VERSION ""

NS_ :

BS_:

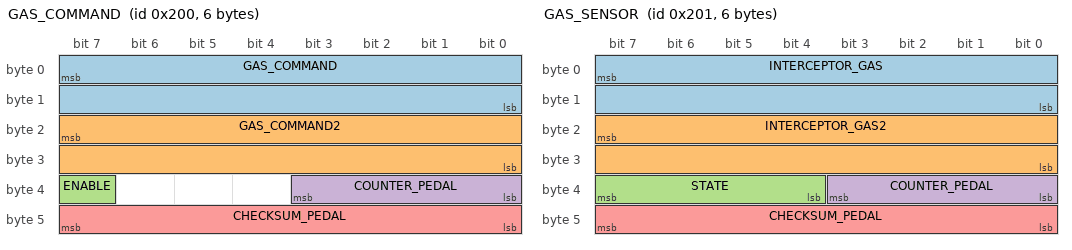
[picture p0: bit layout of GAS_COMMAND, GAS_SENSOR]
BO_ 512 GAS_COMMAND: 6 EON
 SG_ GAS_COMMAND : 7|16@0+ (0.253984064,-83.3) [0|1] "" INTERCEPTOR
 SG_ GAS_COMMAND2 : 23|16@0+ (0.126992032,-83.3) [0|1] "" INTERCEPTOR
 SG_ ENABLE : 39|1@0+ (1,0) [0|1] "" INTERCEPTOR
 SG_ COUNTER_PEDAL : 35|4@0+ (1,0) [0|15] "" INTERCEPTOR
 SG_ CHECKSUM_PEDAL : 47|8@0+ (1,0) [0|255] "" INTERCEPTOR

BO_ 513 GAS_SENSOR: 6 INTERCEPTOR
 SG_ INTERCEPTOR_GAS : 7|16@0+ (1,0) [0|1] "" EON
 SG_ INTERCEPTOR_GAS2 : 23|16@0+ (1,0) [0|1] "" EON
 SG_ STATE : 39|4@0+ (1,0) [0|15] "" EON
 SG_ COUNTER_PEDAL : 35|4@0+ (1,0) [0|15] "" EON
 SG_ CHECKSUM_PEDAL : 47|8@0+ (1,0) [0|255] "" EON

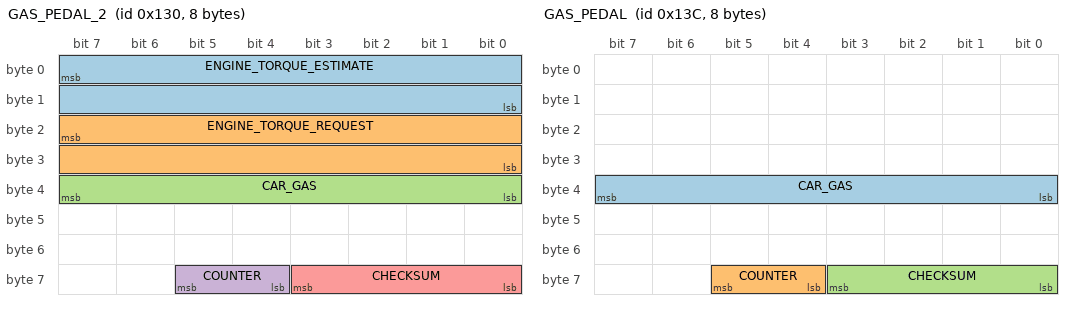
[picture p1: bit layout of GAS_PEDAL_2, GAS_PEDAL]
BO_ 304 GAS_PEDAL_2: 8 PCM
 SG_ ENGINE_TORQUE_ESTIMATE : 7|16@0- (1,0) [-1000|1000] "Nm" EON
 SG_ ENGINE_TORQUE_REQUEST : 23|16@0- (1,0) [-1000|1000] "Nm" EON
 SG_ CAR_GAS : 39|8@0+ (1,0) [0|255] "" EON
 SG_ COUNTER : 61|2@0+ (1,0) [0|3] "" EON
 SG_ CHECKSUM : 59|4@0+ (1,0) [0|15] "" EON

BO_ 316 GAS_PEDAL: 8 PCM
 SG_ CAR_GAS : 39|8@0+ (1,0) [0|255] "" EON
 SG_ COUNTER : 61|2@0+ (1,0) [0|3] "" EON
 SG_ CHECKSUM : 59|4@0+ (1,0) [0|15] "" EON

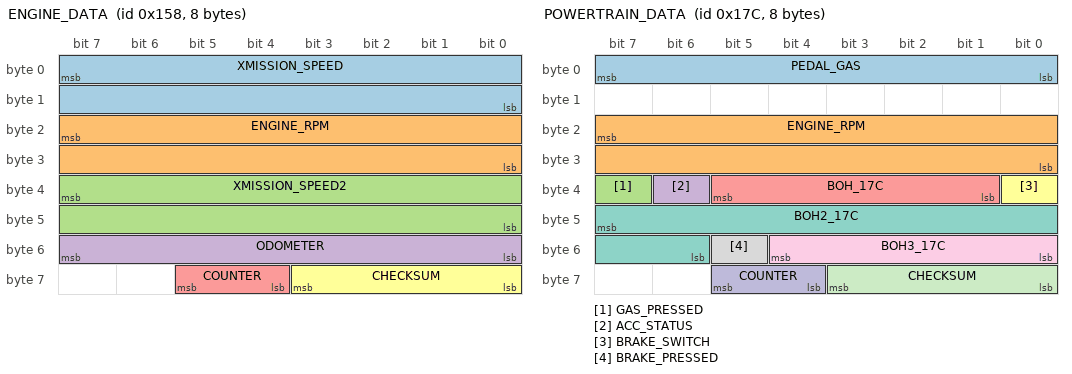
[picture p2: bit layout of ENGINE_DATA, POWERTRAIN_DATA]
BO_ 344 ENGINE_DATA: 8 PCM
 SG_ XMISSION_SPEED : 7|16@0+ (0.01,0) [0|250] "kph" EON
 SG_ ENGINE_RPM : 23|16@0+ (1,0) [0|15000] "rpm" EON
 SG_ XMISSION_SPEED2 : 39|16@0+ (0.01,0) [0|250] "kph" EON
 SG_ ODOMETER : 55|8@0+ (10,0) [0|2550] "m" XXX
 SG_ COUNTER : 61|2@0+ (1,0) [0|3] "" EON
 SG_ CHECKSUM : 59|4@0+ (1,0) [0|15] "" EON

BO_ 380 POWERTRAIN_DATA: 8 PCM
 SG_ PEDAL_GAS : 7|8@0+ (1,0) [0|255] "" EON
 SG_ ENGINE_RPM : 23|16@0+ (1,0) [0|15000] "rpm" EON
 SG_ GAS_PRESSED : 39|1@0+ (1,0) [0|1] "" EON
 SG_ ACC_STATUS : 38|1@0+ (1,0) [0|1] "" EON
 SG_ BOH_17C : 37|5@0+ (1,0) [0|1] "" EON
 SG_ BRAKE_SWITCH : 32|1@0+ (1,0) [0|1] "" EON
 SG_ BOH2_17C : 47|10@0+ (1,0) [0|1] "" EON
 SG_ BRAKE_PRESSED : 53|1@0+ (1,0) [0|1] "" EON
 SG_ BOH3_17C : 52|5@0+ (1,0) [0|1] "" EON
 SG_ COUNTER : 61|2@0+ (1,0) [0|3] "" EON
 SG_ CHECKSUM : 59|4@0+ (1,0) [0|15] "" EON

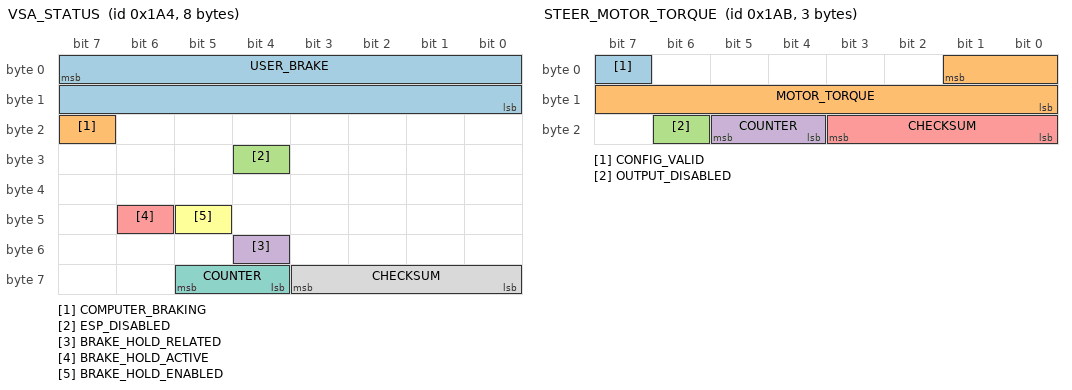
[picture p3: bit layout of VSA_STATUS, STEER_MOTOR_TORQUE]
BO_ 420 VSA_STATUS: 8 VSA
 SG_ USER_BRAKE : 7|16@0+ (0.015625,-1.609375) [0|1000] "" EON
 SG_ COMPUTER_BRAKING : 23|1@0+ (1,0) [0|1] "" EON
 SG_ ESP_DISABLED : 28|1@0+ (1,0) [0|1] "" EON
 SG_ BRAKE_HOLD_RELATED : 52|1@0+ (1,0) [0|1] "" XXX
 SG_ BRAKE_HOLD_ACTIVE : 46|1@0+ (1,0) [0|1] "" EON
 SG_ BRAKE_HOLD_ENABLED : 45|1@0+ (1,0) [0|1] "" EON
 SG_ COUNTER : 61|2@0+ (1,0) [0|3] "" EON
 SG_ CHECKSUM : 59|4@0+ (1,0) [0|15] "" EON

BO_ 427 STEER_MOTOR_TORQUE: 3 EPS
 SG_ CONFIG_VALID : 7|1@0+ (1,0) [0|1] "" EON
 SG_ MOTOR_TORQUE : 1|10@0+ (1,0) [0|256] "" EON
 SG_ OUTPUT_DISABLED : 22|1@0+ (1,0) [0|1] "" EON
 SG_ COUNTER : 21|2@0+ (1,0) [0|3] "" EON
 SG_ CHECKSUM : 19|4@0+ (1,0) [0|15] "" EON

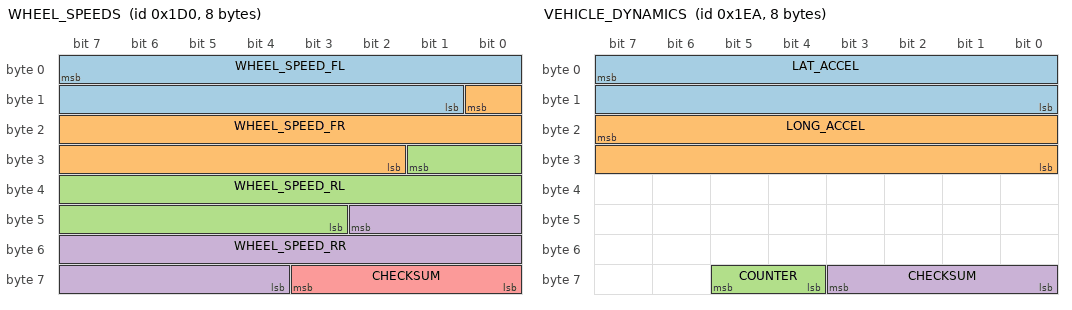
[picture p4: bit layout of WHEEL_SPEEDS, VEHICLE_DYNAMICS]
BO_ 464 WHEEL_SPEEDS: 8 VSA
 SG_ WHEEL_SPEED_FL : 7|15@0+ (0.01,0) [0|250] "kph" EON
 SG_ WHEEL_SPEED_FR : 8|15@0+ (0.01,0) [0|250] "kph" EON
 SG_ WHEEL_SPEED_RL : 25|15@0+ (0.01,0) [0|250] "kph" EON
 SG_ WHEEL_SPEED_RR : 42|15@0+ (0.01,0) [0|250] "kph" EON
 SG_ CHECKSUM : 59|4@0+ (1,0) [0|3] "" EON

BO_ 490 VEHICLE_DYNAMICS: 8 VSA
 SG_ LAT_ACCEL : 7|16@0- (0.0015,0) [-20|20] "m/s2" EON
 SG_ LONG_ACCEL : 23|16@0- (0.0015,0) [-20|20] "m/s2" EON
 SG_ COUNTER : 61|2@0+ (1,0) [0|3] "" EON
 SG_ CHECKSUM : 59|4@0+ (1,0) [0|3] "" EON

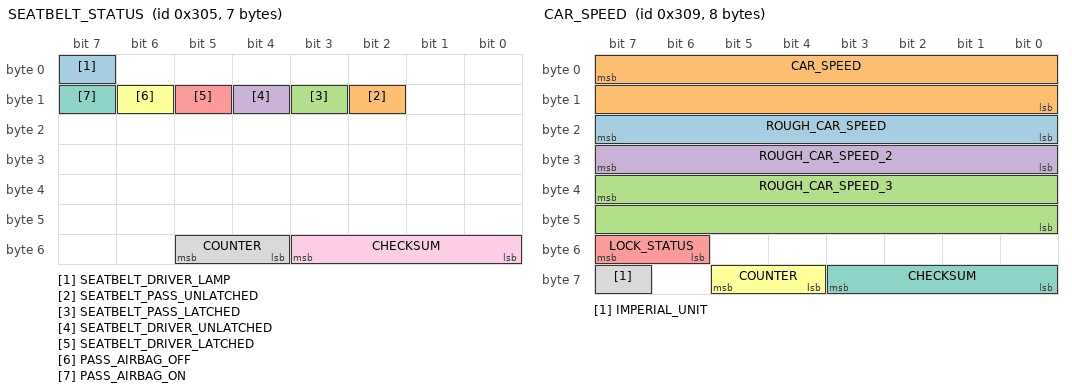
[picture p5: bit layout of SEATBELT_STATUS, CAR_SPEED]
BO_ 773 SEATBELT_STATUS: 7 BDY
 SG_ SEATBELT_DRIVER_LAMP : 7|1@0+ (1,0) [0|1] "" EON
 SG_ SEATBELT_PASS_UNLATCHED : 10|1@0+ (1,0) [0|1] "" EON
 SG_ SEATBELT_PASS_LATCHED : 11|1@0+ (1,0) [0|1] "" EON
 SG_ SEATBELT_DRIVER_UNLATCHED : 12|1@0+ (1,0) [0|1] "" EON
 SG_ SEATBELT_DRIVER_LATCHED : 13|1@0+ (1,0) [0|1] "" EON
 SG_ PASS_AIRBAG_OFF : 14|1@0+ (1,0) [0|1] "" EON
 SG_ PASS_AIRBAG_ON : 15|1@0+ (1,0) [0|1] "" EON
 SG_ COUNTER : 53|2@0+ (1,0) [0|3] "" EON
 SG_ CHECKSUM : 51|4@0+ (1,0) [0|3] "" EON

BO_ 777 CAR_SPEED: 8 PCM
 SG_ ROUGH_CAR_SPEED : 23|8@0+ (1,0) [0|255] "mph" XXX
 SG_ CAR_SPEED : 7|16@0+ (0.01,0) [0|65535] "kph" XXX
 SG_ ROUGH_CAR_SPEED_3 : 39|16@0+ (0.01,0) [0|65535] "kph" XXX
 SG_ ROUGH_CAR_SPEED_2 : 31|8@0+ (1,0) [0|255] "mph" XXX
 SG_ LOCK_STATUS : 55|2@0+ (1,0) [0|255] "" XXX
 SG_ COUNTER : 61|2@0+ (1,0) [0|3] "" XXX
 SG_ CHECKSUM : 59|4@0+ (1,0) [0|15] "" XXX
 SG_ IMPERIAL_UNIT : 63|1@0+ (1,0) [0|1] "" XXX

BO_ 780 ACC_HUD: 8 ADAS
 SG_ PCM_SPEED : 7|16@0+ (0.01,0) [0|250] "kph" BDY
 SG_ PCM_GAS : 23|8@0+ (1,0) [0|127] "" BDY
 SG_ CRUISE_SPEED : 31|8@0+ (1,0) [0|255] "kph" BDY
 SG_ DTC_MODE : 39|1@0+ (1,0) [0|1] "" BDY
 SG_ BOH : 38|1@0+ (1,0) [0|1] "" BDY
 SG_ ACC_PROBLEM : 37|1@0+ (1,0) [0|1] "" BDY
 SG_ FCM_OFF : 35|1@0+ (1,0) [0|1] "" BDY
 SG_ FCM_OFF_2 : 36|1@0+ (1,0) [0|1] "" BDY
 SG_ FCM_PROBLEM : 34|1@0+ (1,0) [0|1] "" BDY
 SG_ RADAR_OBSTRUCTED : 33|1@0+ (1,0) [0|1] "" BDY
 SG_ ENABLE_MINI_CAR : 32|1@0+ (1,0) [0|1] "" BDY
 SG_ HUD_DISTANCE : 47|2@0+ (1,0) [0|3] "" BDY
 SG_ HUD_LEAD : 45|2@0+ (1,0) [0|3] "" BDY
 SG_ BOH_3 : 43|1@0+ (1,0) [0|3] "" BDY
 SG_ BOH_4 : 42|1@0+ (1,0) [0|3] "" BDY
 SG_ BOH_5 : 41|1@0+ (1,0) [0|3] "" BDY
 SG_ CRUISE_CONTROL_LABEL : 40|1@0+ (1,0) [0|3] "" BDY
 SG_ SET_ME_X01_2 : 55|1@0+ (1,0) [0|1] "" BDY
 SG_ IMPERIAL_UNIT : 54|1@0+ (1,0) [0|1] "" BDY
 SG_ ACC_ON : 52|1@0+ (1,0) [0|1] "" BDY
 SG_ CHIME : 51|3@0+ (1,0) [0|1] "" BDY
 SG_ SET_ME_X01 : 48|1@0+ (1,0) [0|1] "" BDY
 SG_ ICONS : 63|2@0+ (1,0) [0|1] "" BDY
 SG_ COUNTER : 61|2@0+ (1,0) [0|3] "" BDY
 SG_ CHECKSUM : 59|4@0+ (1,0) [0|3] "" BDY

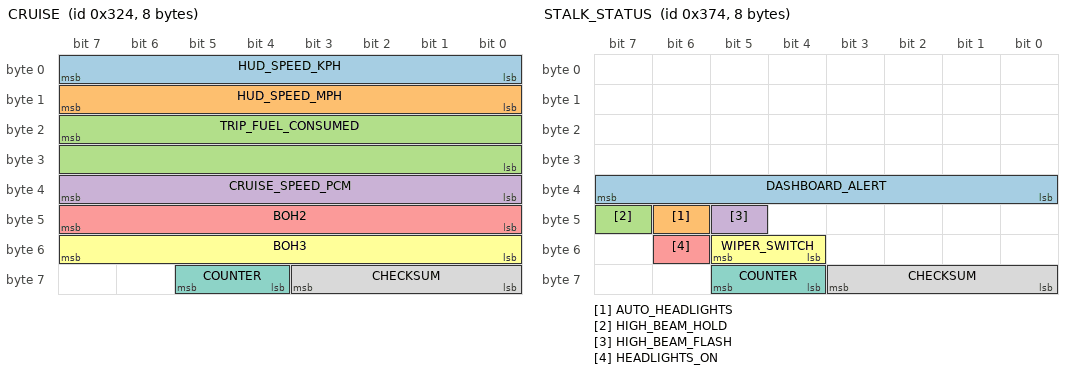
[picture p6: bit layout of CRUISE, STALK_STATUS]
BO_ 804 CRUISE: 8 PCM
 SG_ HUD_SPEED_KPH : 7|8@0+ (1,0) [0|255] "kph" EON
 SG_ HUD_SPEED_MPH : 15|8@0+ (1,0) [0|255] "mph" EON
 SG_ TRIP_FUEL_CONSUMED : 23|16@0+ (1,0) [0|255] "" EON
 SG_ CRUISE_SPEED_PCM : 39|8@0+ (1,0) [0|255] "" EON
 SG_ BOH2 : 47|8@0- (1,0) [0|255] "" EON
 SG_ BOH3 : 55|8@0+ (1,0) [0|255] "" EON
 SG_ COUNTER : 61|2@0+ (1,0) [0|3] "" EON
 SG_ CHECKSUM : 59|4@0+ (1,0) [0|15] "" EON

BO_ 884 STALK_STATUS: 8 XXX
 SG_ DASHBOARD_ALERT : 39|8@0+ (1,0) [0|255] "" EON
 SG_ AUTO_HEADLIGHTS : 46|1@0+ (1,0) [0|1] "" EON
 SG_ HIGH_BEAM_HOLD : 47|1@0+ (1,0) [0|1] "" EON
 SG_ HIGH_BEAM_FLASH : 45|1@0+ (1,0) [0|1] "" EON
 SG_ HEADLIGHTS_ON : 54|1@0+ (1,0) [0|1] "" EON
 SG_ WIPER_SWITCH : 53|2@0+ (1,0) [0|3] "" XXX
 SG_ COUNTER : 61|2@0+ (1,0) [0|3] "" EON
 SG_ CHECKSUM : 59|4@0+ (1,0) [0|15] "" EON

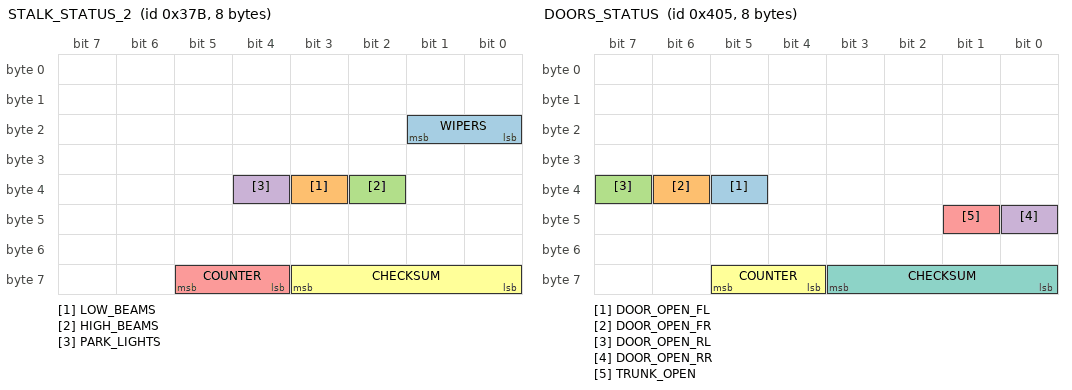
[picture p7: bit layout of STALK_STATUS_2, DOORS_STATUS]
BO_ 891 STALK_STATUS_2: 8 XXX
 SG_ WIPERS : 17|2@0+ (1,0) [0|3] "" EON
 SG_ LOW_BEAMS : 35|1@0+ (1,0) [0|1] "" XXX
 SG_ HIGH_BEAMS : 34|1@0+ (1,0) [0|1] "" XXX
 SG_ PARK_LIGHTS : 36|1@0+ (1,0) [0|1] "" XXX
 SG_ COUNTER : 61|2@0+ (1,0) [0|3] "" EON
 SG_ CHECKSUM : 59|4@0+ (1,0) [0|15] "" EON

BO_ 1029 DOORS_STATUS: 8 BDY
 SG_ DOOR_OPEN_FL : 37|1@0+ (1,0) [0|1] "" EON
 SG_ DOOR_OPEN_FR : 38|1@0+ (1,0) [0|1] "" EON
 SG_ DOOR_OPEN_RL : 39|1@0+ (1,0) [0|1] "" EON
 SG_ DOOR_OPEN_RR : 40|1@0+ (1,0) [0|1] "" EON
 SG_ TRUNK_OPEN : 41|1@0+ (1,0) [0|1] "" EON
 SG_ COUNTER : 61|2@0+ (1,0) [0|3] "" EON
 SG_ CHECKSUM : 59|4@0+ (1,0) [0|15] "" EON

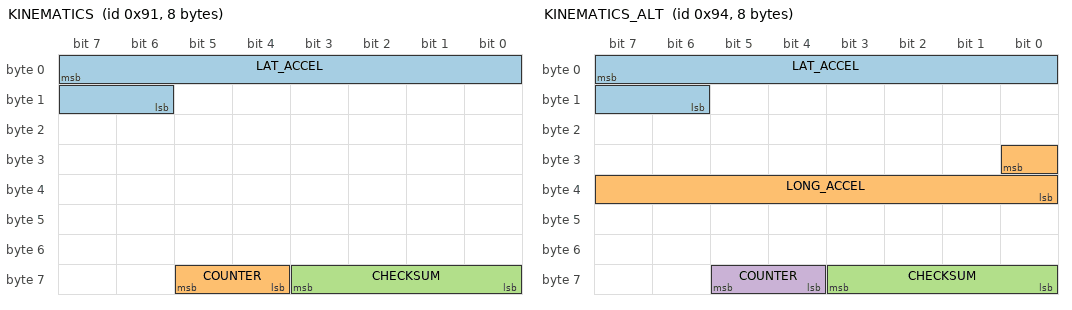
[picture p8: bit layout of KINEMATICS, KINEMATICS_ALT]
BO_ 145 KINEMATICS: 8 XXX
 SG_ LAT_ACCEL : 7|10@0+ (0.02,-512) [-20|20] "m/s2" EON
 SG_ COUNTER : 61|2@0+ (1,0) [0|3] "" EON
 SG_ CHECKSUM : 59|4@0+ (1,0) [0|3] "" EON

BO_ 148 KINEMATICS_ALT: 8 XXX
 SG_ LAT_ACCEL : 7|10@0+ (0.02,-512) [-20|20] "m/s2" EON
 SG_ LONG_ACCEL : 24|9@0- (-0.02,0) [-20|20] "m/s2" EON
 SG_ CHECKSUM : 59|4@0+ (1,0) [0|3] "" EON
 SG_ COUNTER : 61|2@0+ (1,0) [0|3] "" EON

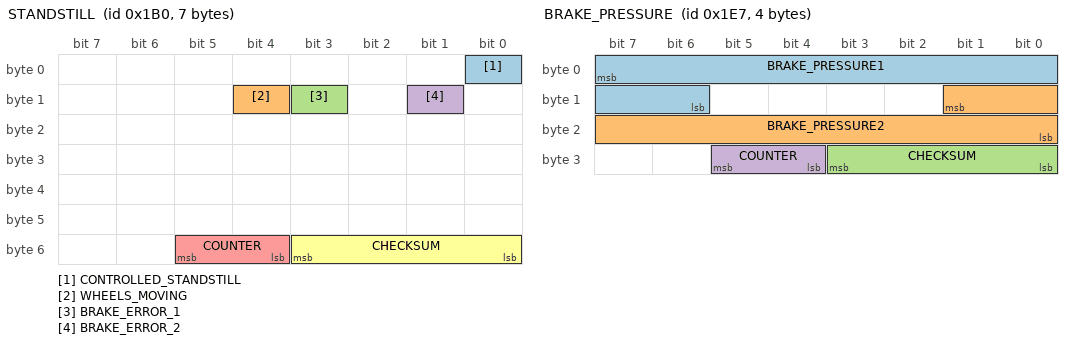
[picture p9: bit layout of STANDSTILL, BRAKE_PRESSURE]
BO_ 432 STANDSTILL: 7 VSA
 SG_ CONTROLLED_STANDSTILL : 0|1@0+ (1,0) [0|1] "" EON
 SG_ WHEELS_MOVING : 12|1@0+ (1,0) [0|1] "" EON
 SG_ BRAKE_ERROR_1 : 11|1@0+ (1,0) [0|1] "" EON
 SG_ BRAKE_ERROR_2 : 9|1@0+ (1,0) [0|1] "" EON
 SG_ COUNTER : 53|2@0+ (1,0) [0|3] "" EON
 SG_ CHECKSUM : 51|4@0+ (1,0) [0|3] "" EON

BO_ 487 BRAKE_PRESSURE: 4 VSA
 SG_ BRAKE_PRESSURE1 : 7|10@0+ (0.015625,-103) [0|1000] "" EON
 SG_ BRAKE_PRESSURE2 : 9|10@0+ (0.015625,-103) [0|1000] "" EON
 SG_ CHECKSUM : 27|4@0+ (1,0) [0|15] "" EON
 SG_ COUNTER : 29|2@0+ (1,0) [0|3] "" EON

BO_ 506 BRAKE_COMMAND: 8 ADAS
 SG_ COMPUTER_BRAKE : 7|10@0+ (1,0) [0|1] "" EBCM
 SG_ BRAKE_PUMP_REQUEST : 8|1@0+ (1,0) [0|1] "" EBCM
 SG_ BRAKE_PUMP_REQUEST_ALT : 11|1@0+ (1,0) [0|1] "" EBCM
 SG_ SET_ME_X00 : 23|3@0+ (1,0) [0|1] "" EBCM
 SG_ CRUISE_OVERRIDE : 20|1@0+ (1,0) [0|1] "" EBCM
 SG_ SET_ME_X00_2 : 19|1@0+ (1,0) [0|1] "" EBCM
 SG_ CRUISE_FAULT_CMD : 18|1@0+ (1,0) [0|1] "" EBCM
 SG_ CRUISE_CANCEL_CMD : 17|1@0+ (1,0) [0|1] "" EBCM
 SG_ COMPUTER_BRAKE_REQUEST : 16|1@0+ (1,0) [0|1] "" EBCM
 SG_ SET_ME_1 : 31|1@0+ (1,0) [0|1] "" EBCM
 SG_ AEB_REQ_1 : 29|1@0+ (1,0) [0|1] "" XXX
 SG_ AEB_REQ_2 : 26|3@0+ (1,0) [0|7] "" XXX
 SG_ BRAKE_LIGHTS : 39|1@0+ (1,0) [0|1] "" EBCM
 SG_ CRUISE_STATES : 38|7@0+ (1,0) [0|1] "" EBCM
 SG_ CHIME : 47|3@0+ (1,0) [0|7] "" EBCM
 SG_ SET_ME_X00_3 : 44|1@0+ (1,0) [0|1] "" EBCM
 SG_ FCW : 43|2@0+ (1,0) [0|3] "" EBCM
 SG_ AEB_STATUS : 41|2@0+ (1,0) [0|3] "" XXX
 SG_ COMPUTER_BRAKE_ALT : 55|10@0+ (1,0) [0|0] "" EBCM
 SG_ COUNTER : 61|2@0+ (1,0) [0|3] "" EBCM
 SG_ CHECKSUM : 59|4@0+ (1,0) [0|15] "" EBCM

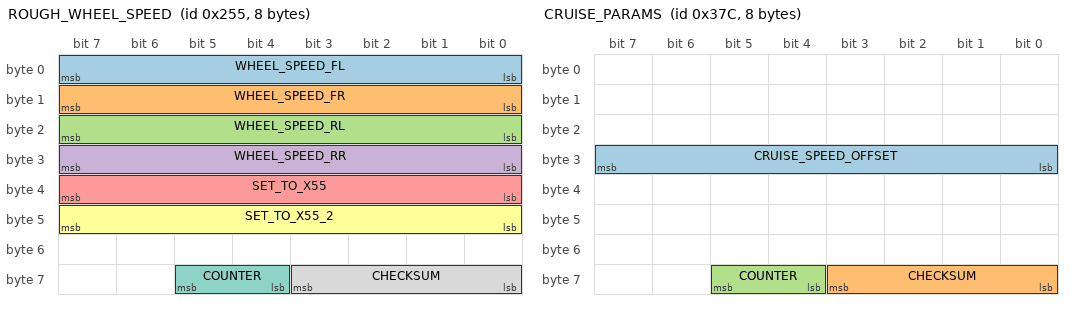
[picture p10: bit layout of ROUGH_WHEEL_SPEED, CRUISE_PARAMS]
BO_ 597 ROUGH_WHEEL_SPEED: 8 VSA
 SG_ WHEEL_SPEED_FL : 7|8@0+ (1,0) [0|255] "mph" EON
 SG_ WHEEL_SPEED_FR : 15|8@0+ (1,0) [0|255] "mph" EON
 SG_ WHEEL_SPEED_RL : 23|8@0+ (1,0) [0|255] "mph" EON
 SG_ WHEEL_SPEED_RR : 31|8@0+ (1,0) [0|255] "mph" EON
 SG_ SET_TO_X55 : 39|8@0+ (1,0) [0|255] "" EON
 SG_ SET_TO_X55_2 : 47|8@0+ (1,0) [0|255] "" EON
 SG_ COUNTER : 61|2@0+ (1,0) [0|3] "" EON
 SG_ CHECKSUM : 59|4@0+ (1,0) [0|15] "" EON

BO_ 829 LKAS_HUD: 5 ADAS
 SG_ CAM_TEMP_HIGH : 7|1@0+ (1,0) [0|255] "" BDY
 SG_ SET_ME_X41 : 6|7@0+ (1,0) [0|127] "" BDY
 SG_ BOH : 6|7@0+ (1,0) [0|127] "" BDY
 SG_ DASHED_LANES : 14|1@0+ (1,0) [0|1] "" BDY
 SG_ DTC : 13|1@0+ (1,0) [0|1] "" BDY
 SG_ LKAS_PROBLEM : 12|1@0+ (1,0) [0|1] "" BDY
 SG_ LKAS_OFF : 11|1@0+ (1,0) [0|1] "" BDY
 SG_ SOLID_LANES : 10|1@0+ (1,0) [0|1] "" BDY
 SG_ LDW_RIGHT : 9|1@0+ (1,0) [0|1] "" BDY
 SG_ STEERING_REQUIRED : 8|1@0+ (1,0) [0|1] "" BDY
 SG_ BOH_2 : 23|2@0+ (1,0) [0|4] "" BDY
 SG_ LDW_PROBLEM : 21|1@0+ (1,0) [0|1] "" BDY
 SG_ BEEP : 17|2@0+ (1,0) [0|1] "" BDY
 SG_ LDW_ON : 28|1@0+ (1,0) [0|1] "" BDY
 SG_ LDW_OFF : 27|1@0+ (1,0) [0|1] "" BDY
 SG_ CLEAN_WINDSHIELD : 26|1@0+ (1,0) [0|1] "" BDY
 SG_ SET_ME_X48 : 31|8@0+ (1,0) [0|255] "" BDY
 SG_ COUNTER : 37|2@0+ (1,0) [0|3] "" BDY
 SG_ CHECKSUM : 35|4@0+ (1,0) [0|15] "" BDY

BO_ 892 CRUISE_PARAMS: 8 PCM
 SG_ CRUISE_SPEED_OFFSET : 31|8@0- (0.1,0) [-128|127] "kph" EON
 SG_ CHECKSUM : 59|4@0+ (1,0) [0|3] "" EON
 SG_ COUNTER : 61|2@0+ (1,0) [0|3] "" EON

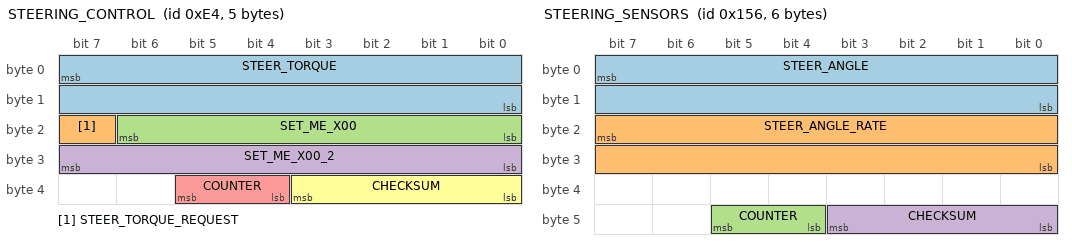
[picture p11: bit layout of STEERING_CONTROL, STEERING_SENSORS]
BO_ 228 STEERING_CONTROL: 5 ADAS
 SG_ STEER_TORQUE : 7|16@0- (1,0) [-3840|3840] "" EPS
 SG_ STEER_TORQUE_REQUEST : 23|1@0+ (1,0) [0|1] "" EPS
 SG_ SET_ME_X00 : 22|7@0+ (1,0) [0|127] "" EPS
 SG_ SET_ME_X00_2 : 31|8@0+ (1,0) [0|0] "" EPS
 SG_ COUNTER : 37|2@0+ (1,0) [0|3] "" EPS
 SG_ CHECKSUM : 35|4@0+ (1,0) [0|15] "" EPS

BO_ 342 STEERING_SENSORS: 6 EPS
 SG_ STEER_ANGLE : 7|16@0- (-0.1,0) [-500|500] "deg" EON
 SG_ STEER_ANGLE_RATE : 23|16@0- (1,0) [-3000|3000] "deg/s" EON
 SG_ COUNTER : 45|2@0+ (1,0) [0|3] "" EON
 SG_ CHECKSUM : 43|4@0+ (1,0) [0|3] "" EON

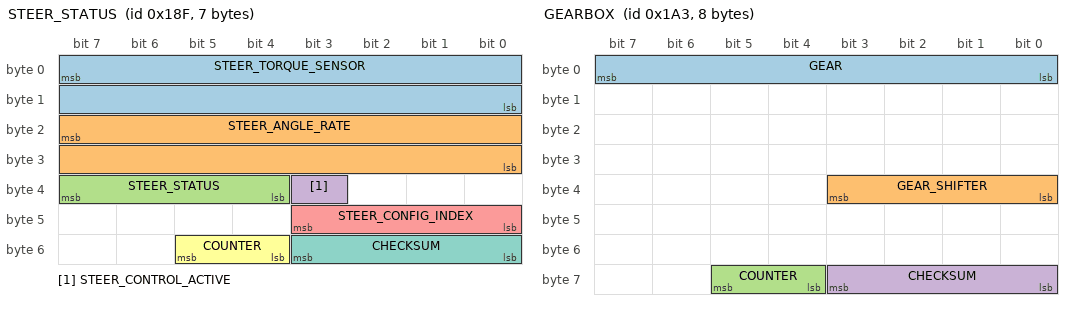
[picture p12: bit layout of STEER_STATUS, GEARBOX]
BO_ 399 STEER_STATUS: 7 EPS
 SG_ STEER_TORQUE_SENSOR : 7|16@0- (-1,0) [-31000|31000] "tbd" EON
 SG_ STEER_ANGLE_RATE : 23|16@0- (-0.1,0) [-31000|31000] "deg/s" EON
 SG_ STEER_STATUS : 39|4@0+ (1,0) [0|15] "" EON
 SG_ STEER_CONTROL_ACTIVE : 35|1@0+ (1,0) [0|1] "" EON
 SG_ STEER_CONFIG_INDEX : 43|4@0+ (1,0) [0|15] "" EON
 SG_ COUNTER : 53|2@0+ (1,0) [0|3] "" EON
 SG_ CHECKSUM : 51|4@0+ (1,0) [0|3] "" EON

BO_ 419 GEARBOX: 8 PCM
 SG_ GEAR : 7|8@0+ (1,0) [0|256] "" EON
 SG_ GEAR_SHIFTER : 35|4@0+ (1,0) [0|15] "" EON
 SG_ COUNTER : 61|2@0+ (1,0) [0|3] "" EON
 SG_ CHECKSUM : 59|4@0+ (1,0) [0|3] "" EON

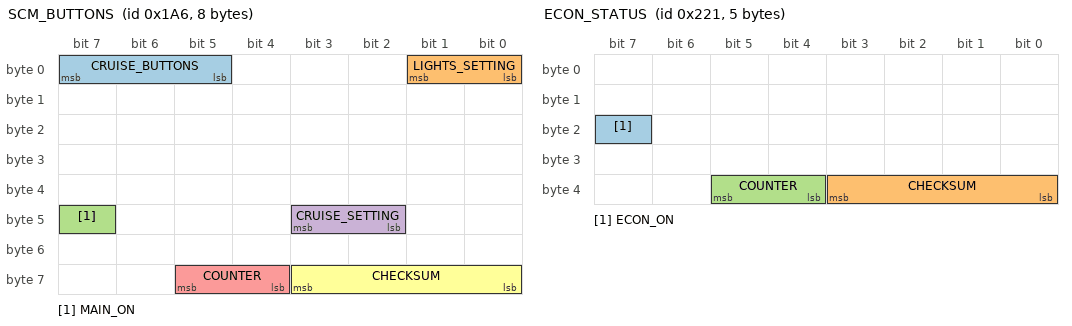
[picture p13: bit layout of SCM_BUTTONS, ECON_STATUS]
BO_ 422 SCM_BUTTONS: 8 SCM
 SG_ CRUISE_BUTTONS : 7|3@0+ (1,0) [0|7] "" EON
 SG_ LIGHTS_SETTING : 1|2@0+ (1,0) [0|3] "" EON
 SG_ MAIN_ON : 47|1@0+ (1,0) [0|1] "" EON
 SG_ CRUISE_SETTING : 43|2@0+ (1,0) [0|3] "" EON
 SG_ COUNTER : 61|2@0+ (1,0) [0|3] "" EON
 SG_ CHECKSUM : 59|4@0+ (1,0) [0|3] "" EON

BO_ 545 ECON_STATUS: 5 XXX
 SG_ ECON_ON : 23|1@0+ (1,0) [0|1] "" EON
 SG_ CHECKSUM : 35|4@0+ (1,0) [0|3] "" EON
 SG_ COUNTER : 37|2@0+ (1,0) [0|3] "" EON

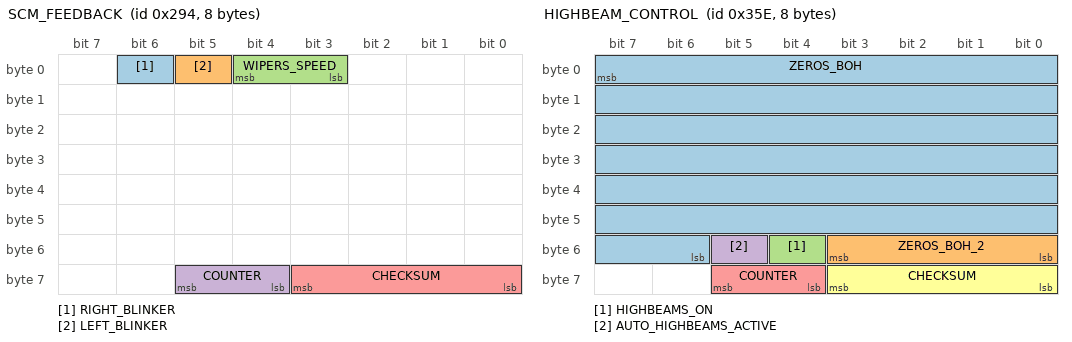
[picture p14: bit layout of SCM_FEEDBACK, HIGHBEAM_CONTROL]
BO_ 660 SCM_FEEDBACK: 8 SCM
 SG_ RIGHT_BLINKER : 6|1@0+ (1,0) [0|1] "" EON
 SG_ LEFT_BLINKER : 5|1@0+ (1,0) [0|1] "" EON
 SG_ WIPERS_SPEED : 4|2@0+ (1,0) [0|3] "" EON
 SG_ COUNTER : 61|2@0+ (1,0) [0|3] "" EON
 SG_ CHECKSUM : 59|4@0+ (1,0) [0|15] "" EON

BO_ 862 HIGHBEAM_CONTROL: 8 ADAS
 SG_ ZEROS_BOH : 7|50@0+ (1,0) [0|127] "" BDY
 SG_ ZEROS_BOH_2 : 48|4@1+ (1,0) [0|15] "" XXX
 SG_ HIGHBEAMS_ON : 52|1@0+ (1,0) [0|1] "" XXX
 SG_ AUTO_HIGHBEAMS_ACTIVE : 53|1@0+ (1,0) [0|1] "" XXX
 SG_ COUNTER : 61|2@0+ (1,0) [0|3] "" XXX
 SG_ CHECKSUM : 59|4@0+ (1,0) [0|15] "" XXX

BO_ 927 RADAR_HUD: 8 ADAS
 SG_ ZEROS_BOH : 7|17@0+ (1,0) [0|127] "" BDY
 SG_ APPLY_BRAKES_FOR_CANC : 23|1@0+ (1,0) [0|15] "" BDY
 SG_ ZEROS_BOH2 : 31|8@0+ (1,0) [0|127] "" BDY
 SG_ RESUME_INSTRUCTION : 21|1@0+ (1,0) [0|15] "" BDY
 SG_ ACC_ALERTS : 20|5@0+ (1,0) [0|15] "" BDY
 SG_ LEAD_SPEED : 39|9@0+ (1,0) [0|127] "" BDY
 SG_ LEAD_STATE : 46|3@0+ (1,0) [0|127] "" BDY
 SG_ LEAD_DISTANCE : 43|5@0+ (1,0) [0|31] "" BDY
 SG_ ZEROS_BOH3 : 54|7@0+ (1,0) [0|127] "" BDY
 SG_ COUNTER : 61|2@0+ (1,0) [0|3] "" BDY
 SG_ CHECKSUM : 59|4@0+ (1,0) [0|15] "" BDY

BU_: XXX

CM_ SG_ 80 Checksumme_Airbag_1 "Checksum Airbag_1";
CM_ SG_ 80 Zaehler_Airbag_1 "Counter Airbag_1";

CM_ SG_ 210 LM_Offset "centiNewton-meters for ease of calculation without FP math in Panda";
CM_ SG_ 210 Vib_Amp "Steering wheel haptic, amplitude";
CM_ SG_ 210 Vib_Freq "Steering wheel haptic, frequency";

CM_ SG_ 416 Zaehler_Bremse_1 "Counter Bremse_1";

CM_ SG_ 640 inneres_Motor_Moment "Engine Indicated Torque";
CM_ SG_ 640 Fahrerwunschmoment "Driver Requested Torque";
CM_ SG_ 640 mechanisches_Motor_Verlustmomen "Mechanical Torque Loss";
CM_ SG_ 640 Fahrpedalwert_oder_Drosselklapp "Accelerator Pedal or Throttle Position";
CM_ SG_ 640 Motordrehzahl "Engine Speed";
CM_ SG_ 640 Momentenangaben_ungenau "Approximate Torque Values";
CM_ SG_ 640 inneres_Motor_Moment_ohne_exter "Inner torque without external";

CM_ SG_ 644 MOB_CHECKSUM "Checksum MOB";
CM_ SG_ 644 MOB_COUNTER "Counter MOB";

CM_ SG_ 648 Minimales_Motormoment_bei_Zuend "Minimum Torque Adjustment";
CM_ SG_ 648 Begrenzungsmoment "Maximum Inner Torque";
CM_ SG_ 648 Bremstestschalter "Brake Test Switch";
CM_ SG_ 648 Soll_Geschwindigkeit_bei_GRA_Be "Desired Vehicle Speed";
CM_ SG_ 648 Bremslichtschalter "Brake Light Switch";
CM_ SG_ 648 Leerlaufsolldrehzahl__Motor_2_ "Target Idle Speed";
CM_ SG_ 648 Fahrzeuggeschwindigkeit "Vehicle Speed";
CM_ SG_ 648 Kuehlmitteltemperatur__Motor_2_ "Coolant Temperature";

CM_ SG_ 896 Drosselklappenpoti "Throttle Position";
CM_ SG_ 896 Motor_Wunschdrehzahl "Desired engine speed";
CM_ SG_ 896 Motordrehzahlbeeinflussung "Shift Target Influence";
CM_ SG_ 896 Fahrpedal_Rohsignal "Accelerator Pedal Position";
CM_ SG_ 896 Ansauglufttemperatur "Intake Air Temperature";
CM_ SG_ 896 Kein_E_Gas "ETB flag";
CM_ SG_ 896 Kein_Start_Stop "Start/stop flag";
CM_ SG_ 896 Rad_Wunschmoment "Desired wheel torque";

CM_ SG_ 912 GK1_Fa_Tuerkont "Status of the driver's door rotary latch";
CM_ SG_ 912 BSK_HL_geoeffnet "Status of the rear left door rotary latch";
CM_ SG_ 912 BSK_HR_geoeffnet "Status of the rear right door rotary latch";
CM_ SG_ 912 BSK_BT_geoeffnet "Status of the passenger door rotary latch";
CM_ SG_ 912 BSK_HD_Hauptraste "Status of trunk lid main detent";

CM_ SG_ 1088 Zaehler_Getriebe_1 "Counter Getriebe_1";
CM_ SG_ 1088 Waehlhebelposition__Getriebe_1_ "Gear Selector Position";
CM_ SG_ 1088 inneres_Soll_Motormoment "Desired Inner Torque";
CM_ SG_ 1088 Schaltabsicht "Shift Intent";
CM_ SG_ 1088 Wandlerverlustmoment "Converter Torque Loss";

CM_ SG_ 1056 Fehlerstatus_Aussentemp__4_1 "ambient temp error";
CM_ SG_ 1056 Fehlerstatus_Oeltemperatur_4_1 "oil temp error";
CM_ SG_ 1056 Fehlerst__Kuehlmitteltemp__4_1 "water temp error";
CM_ SG_ 1056 Aussentemperatur_gefiltert "outside temp, filtered";
CM_ SG_ 1056 Oeltemperatur_4_1 "kombi oil temperature";
CM_ SG_ 1056 Kuehlmitteltemp__4_1__Kombi_2_ "kombi coolant temperature";

CM_ SG_ 1096 Zaehler_Waehlhebel_1 "Counter Waehlhebel_1";

CM_ SG_ 1152 CHECKSUM "Checksum Motor_5";
CM_ SG_ 1152 Anlasser_Ausspuren "Starter Disable";
CM_ SG_ 1152 Anlasser_Freigabe "Starter Release";
CM_ SG_ 1152 Klimadrucksignal__Motor_5_ "Air conditioning pressure signal";
CM_ SG_ 1152 Kraftstoffverbrauchssignal "Fuel consumption signal";
CM_ SG_ 1152 K_hlerluefteransteuerung "Cooling fan control signal";
CM_ SG_ 1152 Klimakompressor_Leistungsreduzi "Air conditioning compressor power reduction flag";
CM_ SG_ 1152 Klimakompressor_aus__Motor_5_ "Air conditioning compressor";
CM_ SG_ 1152 Anlasser_Freigabe "Starter release";
CM_ SG_ 1152 OBD_2_Lampe "OBD light";
CM_ SG_ 1152 E_Gas_Lampe "ETB light";
CM_ SG_ 1152 Ladekontroll_Lampe "Charge light";
CM_ SG_ 1152 Vorgluehlampe__Motor_5_ "Glow light";

CM_ SG_ 1160 Zaehler_Motor_6 "Counter Motor_6";
CM_ SG_ 1160 Hoeheninfo__Motor_6_ "Altitude Correction";
CM_ SG_ 1160 Istmoment_f_r_Getriebe "Actual torque for gear";
CM_ SG_ 1160 Sollmoment_f_r_Getriebe "Target torque for gearbox";
CM_ SG_ 1160 Checksumme_Motor_6 "Checksum Motor_6";
CM_ SG_ 1160 GRA_Sollbeschleunigung "GRA target acceleration";
CM_ SG_ 1160 Ruckmeldung_Momenten "Feedback torque-integral gear intervention";

CM_ SG_ 1344 Zahler_Getriebe_2 "Counter Getriebe_2";
CM_ SG_ 1344 Hochschaltlampe "Upshift Flag";

CM_ SG_ 1386 ACA_V_Wunsch "255=unset";

CM_ SG_ 1408 Zaehler_Motor_Flexia "Counter Motor_Flexia";
CM_ SG_ 1408 Verbrennungsart "Type of combustion";
CM_ SG_ 1408 Max_Drehmoment "Maximum torque";
CM_ SG_ 1408 Drehzahl_MaxNorm "RPM of maximum torque";
CM_ SG_ 1408 Hubraum "Displacement";
CM_ SG_ 1408 Anzahl_Zylinder "Number of cylinders";
CM_ SG_ 1408 Anzahl_Ventile "Number of valves";
CM_ SG_ 1408 Ansaugsystem "Induction System";
CM_ SG_ 1408 Motorleistung "Maximum engine power";

CM_ SG_ 1416 Ladedruck "Boost Pressure";
CM_ SG_ 1416 Motordrehzahlgradient "Engine speed gradient";
CM_ SG_ 1416 Hoeheninfo__Motor_7_ "Altitude correction factor";
CM_ SG_ 1416 Oltemperatur "Oil temperature";

CM_ SG_ 1470 LDW_Direction "0=right,1=left";
CM_ SG_ 1470 XX_DLCORTLC1 "Might be DLC or TLC";
CM_ SG_ 1470 XX_DLCORTLC2 "Might be DLC or TLC, might have wrong size";

CM_ SG_ 1550 MFA_v_Signal_02 "0=km/h, 1=mph";

VAL_ 513 STATE 5 "FAULT_TIMEOUT" 4 "FAULT_STARTUP" 3 "FAULT_SCE" 2 "FAULT_SEND" 1 "FAULT_BAD_CHECKSUM" 0 "NO_FAULT" ;

VAL_ 780 CRUISE_SPEED 255 "no_speed" 252 "stopped";
VAL_ 780 HUD_LEAD 3 "acc_off" 2 "solid_car" 1 "dashed_car" 0 "no_car";
VAL_ 884 DASHBOARD_ALERT 0 "none" 51 "acc_problem" 55 "cmbs_problem" 75 "key_not_detected" 79 "fasten_seatbelt" 111 "lkas_problem" 131 "brake_system_problem" 132 "brake_hold_problem" 139 "tbd" 161 "door_open";
VAL_ 891 WIPERS 4 "High" 2 "Low" 0 "Off";

VAL_ 506 FCW 3 "fcw" 2 "fcw" 1 "fcw" 0 "no_fcw";
VAL_ 506 CHIME 4 "double_chime" 3 "single_chime" 2 "continuous_chime" 1 "repeating_chime" 0 "no_chime";
VAL_ 506 AEB_STATUS 3 "aeb_prepare" 2 "aeb_ready" 1 "aeb_braking" 0 "no_aeb";
VAL_ 829 BEEP 3 "single_beep" 2 "triple_beep" 1 "repeated_beep" 0 "no_beep";

VAL_ 399 STEER_STATUS 6 "tmp_fault" 5 "fault_1" 4 "no_torque_alert_2" 3 "low_speed_lockout" 2 "no_torque_alert_1" 0 "normal" ;
VAL_ 401 GEAR_SHIFTER 32 "L" 16 "S" 8 "D" 4 "N" 2 "R" 1 "P" ;
VAL_ 401 GEAR 7 "L" 10 "S" 4 "D" 3 "N" 2 "R" 1 "P" ;
VAL_ 422 CRUISE_BUTTONS 7 "tbd" 6 "tbd" 5 "tbd" 4 "accel_res" 3 "decel_set" 2 "cancel" 1 "main" 0 "none" ;
VAL_ 422 LIGHTS_SETTING 3 "high_beam" 2 "low_beam" 1 "position" 0 "no_lights" ;
